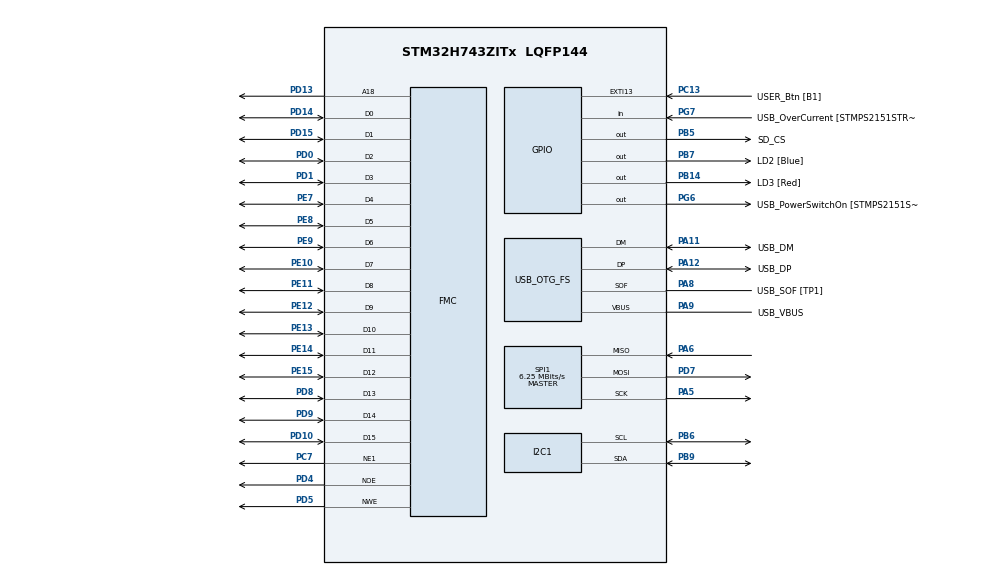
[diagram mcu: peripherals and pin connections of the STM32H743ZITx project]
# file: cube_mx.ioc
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I2C1.Timing=0x10C0ECFF
Mcu.Family=STM32H7
Mcu.Name=STM32H743ZITx
Mcu.Package=LQFP144
NVIC.I2C1_EV_IRQn=true\:10\:0\:true\:false\:true\:true\:true\:true
NVIC.PriorityGroup=NVIC_PRIORITYGROUP_4
NVIC.TIM2_IRQn=true\:1\:0\:true\:false\:true\:false\:true\:true
NVIC.TimeBase=TIM2_IRQn
NVIC.TimeBaseIP=TIM2
PA1.Signal=ETH_RX_CLK
PA10.GPIO_Label=USB_ID
PA10.Signal=USB_OTG_FS_ID
PA11.GPIO_Label=USB_DM
PA11.Mode=Device_Only
PA11.Signal=USB_OTG_FS_DM
PA12.GPIO_Label=USB_DP
PA12.Mode=Device_Only
PA12.Signal=USB_OTG_FS_DP
PA2.GPIO_Label=RMII_MDIO
PA2.Signal=ETH_MDIO
PA5.Mode=Full_Duplex_Master
PA5.Signal=SPI1_SCK
PA6.Mode=Full_Duplex_Master
PA6.Signal=SPI1_MISO
PA7.Signal=ETH_RX_DV
PA8.GPIO_Label=USB_SOF [TP1]
PA8.Mode=Activate_SOF_FS
PA8.Signal=USB_OTG_FS_SOF
PA9.GPIO_Label=USB_VBUS
PA9.Mode=Activate_VBUS
PA9.Signal=USB_OTG_FS_VBUS
PB13.GPIO_Label=RMII_TXD1
PB13.Signal=ETH_TXD1
PB14.GPIO_Label=LD3 [Red]
PB14.Signal=GPIO_Output
PB5.GPIO_Label=SD_CS
PB5.GPIO_Speed=GPIO_SPEED_FREQ_VERY_HIGH
PB5.PinState=GPIO_PIN_SET
PB5.Signal=GPIO_Output
PB6.Mode=I2C
PB6.Signal=I2C1_SCL
PB7.GPIO_Label=LD2 [Blue]
PB7.Signal=GPIO_Output
PB9.Mode=I2C
PB9.Signal=I2C1_SDA
PC1.GPIO_Label=RMII_MDC
PC1.Signal=ETH_MDC
PC13.GPIO_Label=USER_Btn [B1]
PC13.Signal=GPXTI13
PC14-OSC32_IN\ (OSC32_IN).Mode=LSE-External-Oscillator
PC14-OSC32_IN\ (OSC32_IN).Signal=RCC_OSC32_IN
PC15-OSC32_OUT\ (OSC32_OUT).Mode=LSE-External-Oscillator
PC15-OSC32_OUT\ (OSC32_OUT).Signal=RCC_OSC32_OUT
PC4.GPIO_Label=RMII_RXD0
PC4.Signal=ETH_RXD0
PC5.GPIO_Label=RMII_RXD1
PC5.Signal=ETH_RXD1
PC7.Mode=NorPsramChipSelect1_1
PC7.Signal=FMC_NE1
PD0.Signal=FMC_D2_DA2
PD1.Signal=FMC_D3_DA3
PD10.Signal=FMC_D15_DA15
PD13.Signal=FMC_A18
PD14.Signal=FMC_D0_DA0
PD15.Signal=FMC_D1_DA1
PD4.Signal=FMC_NOE
PD5.Signal=FMC_NWE
PD7.Mode=Full_Duplex_Master
PD7.Signal=SPI1_MOSI
PD8.Signal=FMC_D13_DA13
PD9.Signal=FMC_D14_DA14
PE10.Signal=FMC_D7_DA7
PE11.Signal=FMC_D8_DA8
PE12.Signal=FMC_D9_DA9
PE13.Signal=FMC_D10_DA10
PE14.Signal=FMC_D11_DA11
PE15.Signal=FMC_D12_DA12
PE7.Signal=FMC_D4_DA4
PE8.Signal=FMC_D5_DA5
PE9.Signal=FMC_D6_DA6
PG11.GPIO_Label=RMII_TX_EN
PG11.Signal=ETH_TX_EN
PG13.GPIO_Label=RMII_TXD0
PG13.Signal=ETH_TXD0
PG6.GPIO_Label=USB_PowerSwitchOn [STMPS2151STR_EN]
PG6.Signal=GPIO_Output
PG7.GPIO_Label=USB_OverCurrent [STMPS2151STR_FAULT]
PG7.Signal=GPIO_Input
PH0-OSC_IN\ (PH0).GPIO_Label=MCO
PH0-OSC_IN\ (PH0).Mode=HSE-External-Clock-Source
PH0-OSC_IN\ (PH0).Signal=RCC_OSC_IN
PH1-OSC_OUT\ (PH1).Signal=RCC_OSC_OUT
ProjectManager.HeapSize=0x200
ProjectManager.StackSize=0x400
ProjectManager.TargetToolchain=Makefile
RCC.48MHZClocksFreq_Value=24000000
RCC.ADCFreq_Value=16125000
RCC.AHBFreq_Value=216000000
RCC.APB1CLKDivider=RCC_HCLK_DIV4
RCC.APB1Freq_Value=100000000
RCC.APB1TimFreq_Value=108000000
RCC.APB2CLKDivider=RCC_HCLK_DIV2
RCC.APB2Freq_Value=100000000
RCC.APB2TimFreq_Value=216000000
RCC.APB3Freq_Value=100000000
RCC.APB4Freq_Value=100000000
RCC.CortexFreq_Value=400000000
RCC.D1PPRE=RCC_APB3_DIV2
RCC.D2PPRE1=RCC_APB1_DIV2
RCC.D2PPRE2=RCC_APB2_DIV2
RCC.D3PPRE=RCC_APB4_DIV2
RCC.DIVM1=1
RCC.DIVN1=100
RCC.DIVQ1=4
RCC.HCLKFreq_Value=200000000
RCC.HPRE=RCC_HCLK_DIV2
RCC.HSE_VALUE=8000000
RCC.HSI_VALUE=64000000
RCC.PLLM=25
RCC.PLLMUL=RCC_PLL_MUL9
RCC.PLLN=432
RCC.PLLQ=9
RCC.PLLSourceVirtual=RCC_PLLSOURCE_HSE
RCC.PRESCALERUSB=RCC_USBCLKSOURCE_PLL_DIV1_5
RCC.PWR_Regulator_Voltage_Scale=PWR_REGULATOR_VOLTAGE_SCALE1
RCC.SYSCLKFreq_VALUE=400000000
RCC.SYSCLKSource=RCC_SYSCLKSOURCE_PLLCLK
RCC.SYSCLKSourceVirtual=RCC_SYSCLKSOURCE_PLLCLK
RCC.USBCLockSelection=RCC_USBCLKSOURCE_HSI48
RCC.USBFreq_Value=48000000
RCC.VCOOutputFreq_Value=432000000
SH.FMC_A18.0=FMC_A18,A18_1
SH.FMC_D0_DA0.0=FMC_D0,16b-d1
SH.FMC_D10_DA10.0=FMC_D10,16b-d1
SH.FMC_D11_DA11.0=FMC_D11,16b-d1
SH.FMC_D12_DA12.0=FMC_D12,16b-d1
SH.FMC_D13_DA13.0=FMC_D13,16b-d1
SH.FMC_D14_DA14.0=FMC_D14,16b-d1
SH.FMC_D15_DA15.0=FMC_D15,16b-d1
SH.FMC_D1_DA1.0=FMC_D1,16b-d1
SH.FMC_D2_DA2.0=FMC_D2,16b-d1
SH.FMC_D3_DA3.0=FMC_D3,16b-d1
SH.FMC_D4_DA4.0=FMC_D4,16b-d1
SH.FMC_D5_DA5.0=FMC_D5,16b-d1
SH.FMC_D6_DA6.0=FMC_D6,16b-d1
SH.FMC_D7_DA7.0=FMC_D7,16b-d1
SH.FMC_D8_DA8.0=FMC_D8,16b-d1
SH.FMC_D9_DA9.0=FMC_D9,16b-d1
SH.FMC_NOE.0=FMC_NOE,Lcd1
SH.FMC_NWE.0=FMC_NWE,Lcd1
SPI1.BaudRatePrescaler=SPI_BAUDRATEPRESCALER_32
SPI1.CalculateBaudRate=6.25 MBits/s
SPI1.DataSize=SPI_DATASIZE_8BIT
SPI1.Direction=SPI_DIRECTION_2LINES
SPI1.Mode=SPI_MODE_MASTER
SPI1.VirtualType=VM_MASTER
USB_OTG_FS.VirtualMode=Device_Only
VP_SYS_VS_tim2.Mode=TIM2
board=NUCLEO-H743ZI

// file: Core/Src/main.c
/* USER CODE BEGIN Header */
/**
 ******************************************************************************
 * @file           : main.c
 * @brief          : Main program body
 ******************************************************************************
 * @attention
 *
 * Copyright (c) 2022 STMicroelectronics.
 * All rights reserved.
 *
 * This software is licensed under terms that can be found in the LICENSE file
 * in the root directory of this software component.
 * If no LICENSE file comes with this software, it is provided AS-IS.
 *
 ******************************************************************************
 */
/* USER CODE END Header */
#include "main.h"

/* USER CODE BEGIN Includes */
#include "application.h"

/* USER CODE END Includes */

I2C_HandleTypeDef hi2c1;

SPI_HandleTypeDef hspi1;

PCD_HandleTypeDef hpcd_USB_OTG_FS;

SRAM_HandleTypeDef hsram1;

void SystemClock_Config(void);
static void MX_GPIO_Init(void);
static void MX_USB_OTG_FS_PCD_Init(void);
static void MX_I2C1_Init(void);
static void MX_FMC_Init(void);
static void MX_SPI1_Init(void);

int main(void)
{

  /* MCU Configuration--------------------------------------------------------*/

  /* Reset of all peripherals, Initializes the Flash interface and the Systick. */
  HAL_Init();

  /* Configure the system clock */
  SystemClock_Config();

  /* Initialize all configured peripherals */
  MX_GPIO_Init();
  MX_USB_OTG_FS_PCD_Init();
  MX_I2C1_Init();
  MX_FMC_Init();
  MX_SPI1_Init();
  /* USER CODE BEGIN 2 */
  uint8_t appExitVal = application();
  if (appExitVal != 0)
  {
    // send error code via cli to user
  }
  /* USER CODE END 2 */

  /* Infinite loop */
  while (1)
  {

  }
}

void SystemClock_Config(void)
{
  RCC_OscInitTypeDef RCC_OscInitStruct = {0};
  RCC_ClkInitTypeDef RCC_ClkInitStruct = {0};

  /** Supply configuration update enable
  */
  HAL_PWREx_ConfigSupply(PWR_LDO_SUPPLY);

  /** Configure the main internal regulator output voltage
  */
  __HAL_PWR_VOLTAGESCALING_CONFIG(PWR_REGULATOR_VOLTAGE_SCALE1);

  while(!__HAL_PWR_GET_FLAG(PWR_FLAG_VOSRDY)) {}

  /** Initializes the RCC Oscillators according to the specified parameters
  * in the RCC_OscInitTypeDef structure.
  */
  RCC_OscInitStruct.OscillatorType = RCC_OSCILLATORTYPE_HSI48|RCC_OSCILLATORTYPE_HSE;
  RCC_OscInitStruct.HSEState = RCC_HSE_BYPASS;
  RCC_OscInitStruct.HSI48State = RCC_HSI48_ON;
  RCC_OscInitStruct.PLL.PLLState = RCC_PLL_ON;
  RCC_OscInitStruct.PLL.PLLSource = RCC_PLLSOURCE_HSE;
  RCC_OscInitStruct.PLL.PLLM = 1;
  RCC_OscInitStruct.PLL.PLLN = 100;
  RCC_OscInitStruct.PLL.PLLP = 2;
  RCC_OscInitStruct.PLL.PLLQ = 4;
  RCC_OscInitStruct.PLL.PLLR = 2;
  RCC_OscInitStruct.PLL.PLLRGE = RCC_PLL1VCIRANGE_3;
  RCC_OscInitStruct.PLL.PLLVCOSEL = RCC_PLL1VCOWIDE;
  RCC_OscInitStruct.PLL.PLLFRACN = 0;
  if (HAL_RCC_OscConfig(&RCC_OscInitStruct) != HAL_OK)
  {
    Error_Handler();
  }

  /** Initializes the CPU, AHB and APB buses clocks
  */
  RCC_ClkInitStruct.ClockType = RCC_CLOCKTYPE_HCLK|RCC_CLOCKTYPE_SYSCLK
                              |RCC_CLOCKTYPE_PCLK1|RCC_CLOCKTYPE_PCLK2
                              |RCC_CLOCKTYPE_D3PCLK1|RCC_CLOCKTYPE_D1PCLK1;
  RCC_ClkInitStruct.SYSCLKSource = RCC_SYSCLKSOURCE_PLLCLK;
  RCC_ClkInitStruct.SYSCLKDivider = RCC_SYSCLK_DIV1;
  RCC_ClkInitStruct.AHBCLKDivider = RCC_HCLK_DIV2;
  RCC_ClkInitStruct.APB3CLKDivider = RCC_APB3_DIV2;
  RCC_ClkInitStruct.APB1CLKDivider = RCC_APB1_DIV2;
  RCC_ClkInitStruct.APB2CLKDivider = RCC_APB2_DIV2;
  RCC_ClkInitStruct.APB4CLKDivider = RCC_APB4_DIV2;

  if (HAL_RCC_ClockConfig(&RCC_ClkInitStruct, FLASH_LATENCY_2) != HAL_OK)
  {
    Error_Handler();
  }
}

static void MX_I2C1_Init(void)
{

  hi2c1.Instance = I2C1;
  hi2c1.Init.Timing = 0x10C0ECFF;
  hi2c1.Init.OwnAddress1 = 0;
  hi2c1.Init.AddressingMode = I2C_ADDRESSINGMODE_7BIT;
  hi2c1.Init.DualAddressMode = I2C_DUALADDRESS_DISABLE;
  hi2c1.Init.OwnAddress2 = 0;
  hi2c1.Init.OwnAddress2Masks = I2C_OA2_NOMASK;
  hi2c1.Init.GeneralCallMode = I2C_GENERALCALL_DISABLE;
  hi2c1.Init.NoStretchMode = I2C_NOSTRETCH_DISABLE;
  if (HAL_I2C_Init(&hi2c1) != HAL_OK)
  {
    Error_Handler();
  }

  /** Configure Analogue filter
  */
  if (HAL_I2CEx_ConfigAnalogFilter(&hi2c1, I2C_ANALOGFILTER_ENABLE) != HAL_OK)
  {
    Error_Handler();
  }

  /** Configure Digital filter
  */
  if (HAL_I2CEx_ConfigDigitalFilter(&hi2c1, 0) != HAL_OK)
  {
    Error_Handler();
  }

}

static void MX_SPI1_Init(void)
{

  /* SPI1 parameter configuration*/
  hspi1.Instance = SPI1;
  hspi1.Init.Mode = SPI_MODE_MASTER;
  hspi1.Init.Direction = SPI_DIRECTION_2LINES;
  hspi1.Init.DataSize = SPI_DATASIZE_8BIT;
  hspi1.Init.CLKPolarity = SPI_POLARITY_LOW;
  hspi1.Init.CLKPhase = SPI_PHASE_1EDGE;
  hspi1.Init.NSS = SPI_NSS_SOFT;
  hspi1.Init.BaudRatePrescaler = SPI_BAUDRATEPRESCALER_32;
  hspi1.Init.FirstBit = SPI_FIRSTBIT_MSB;
  hspi1.Init.TIMode = SPI_TIMODE_DISABLE;
  hspi1.Init.CRCCalculation = SPI_CRCCALCULATION_DISABLE;
  hspi1.Init.CRCPolynomial = 0x0;
  hspi1.Init.NSSPMode = SPI_NSS_PULSE_ENABLE;
  hspi1.Init.NSSPolarity = SPI_NSS_POLARITY_LOW;
  hspi1.Init.FifoThreshold = SPI_FIFO_THRESHOLD_01DATA;
  hspi1.Init.TxCRCInitializationPattern = SPI_CRC_INITIALIZATION_ALL_ZERO_PATTERN;
  hspi1.Init.RxCRCInitializationPattern = SPI_CRC_INITIALIZATION_ALL_ZERO_PATTERN;
  hspi1.Init.MasterSSIdleness = SPI_MASTER_SS_IDLENESS_00CYCLE;
  hspi1.Init.MasterInterDataIdleness = SPI_MASTER_INTERDATA_IDLENESS_00CYCLE;
  hspi1.Init.MasterReceiverAutoSusp = SPI_MASTER_RX_AUTOSUSP_DISABLE;
  hspi1.Init.MasterKeepIOState = SPI_MASTER_KEEP_IO_STATE_DISABLE;
  hspi1.Init.IOSwap = SPI_IO_SWAP_DISABLE;
  if (HAL_SPI_Init(&hspi1) != HAL_OK)
  {
    Error_Handler();
  }

}

static void MX_USB_OTG_FS_PCD_Init(void)
{

  hpcd_USB_OTG_FS.Instance = USB_OTG_FS;
  hpcd_USB_OTG_FS.Init.dev_endpoints = 9;
  hpcd_USB_OTG_FS.Init.speed = PCD_SPEED_FULL;
  hpcd_USB_OTG_FS.Init.dma_enable = DISABLE;
  hpcd_USB_OTG_FS.Init.phy_itface = PCD_PHY_EMBEDDED;
  hpcd_USB_OTG_FS.Init.Sof_enable = ENABLE;
  hpcd_USB_OTG_FS.Init.low_power_enable = DISABLE;
  hpcd_USB_OTG_FS.Init.lpm_enable = DISABLE;
  hpcd_USB_OTG_FS.Init.battery_charging_enable = ENABLE;
  hpcd_USB_OTG_FS.Init.vbus_sensing_enable = ENABLE;
  hpcd_USB_OTG_FS.Init.use_dedicated_ep1 = DISABLE;
  if (HAL_PCD_Init(&hpcd_USB_OTG_FS) != HAL_OK)
  {
    Error_Handler();
  }

}

/* FMC initialization function */
static void MX_FMC_Init(void)
{

  FMC_NORSRAM_TimingTypeDef Timing = {0};

  /** Perform the SRAM1 memory initialization sequence
  */
  hsram1.Instance = FMC_NORSRAM_DEVICE;
  hsram1.Extended = FMC_NORSRAM_EXTENDED_DEVICE;
  /* hsram1.Init */
  hsram1.Init.NSBank = FMC_NORSRAM_BANK1;
  hsram1.Init.DataAddressMux = FMC_DATA_ADDRESS_MUX_DISABLE;
  hsram1.Init.MemoryType = FMC_MEMORY_TYPE_SRAM;
  hsram1.Init.MemoryDataWidth = FMC_NORSRAM_MEM_BUS_WIDTH_16;
  hsram1.Init.BurstAccessMode = FMC_BURST_ACCESS_MODE_DISABLE;
  hsram1.Init.WaitSignalPolarity = FMC_WAIT_SIGNAL_POLARITY_LOW;
  hsram1.Init.WaitSignalActive = FMC_WAIT_TIMING_BEFORE_WS;
  hsram1.Init.WriteOperation = FMC_WRITE_OPERATION_ENABLE;
  hsram1.Init.WaitSignal = FMC_WAIT_SIGNAL_DISABLE;
  hsram1.Init.ExtendedMode = FMC_EXTENDED_MODE_DISABLE;
  hsram1.Init.AsynchronousWait = FMC_ASYNCHRONOUS_WAIT_DISABLE;
  hsram1.Init.WriteBurst = FMC_WRITE_BURST_DISABLE;
  hsram1.Init.ContinuousClock = FMC_CONTINUOUS_CLOCK_SYNC_ONLY;
  hsram1.Init.WriteFifo = FMC_WRITE_FIFO_ENABLE;
  hsram1.Init.PageSize = FMC_PAGE_SIZE_NONE;
  /* Timing */
  Timing.AddressSetupTime = 15;
  Timing.AddressHoldTime = 15;
  Timing.DataSetupTime = 255;
  Timing.BusTurnAroundDuration = 15;
  Timing.CLKDivision = 16;
  Timing.DataLatency = 17;
  Timing.AccessMode = FMC_ACCESS_MODE_A;
  /* ExtTiming */

  if (HAL_SRAM_Init(&hsram1, &Timing, NULL) != HAL_OK)
  {
    Error_Handler( );
  }

}

static void MX_GPIO_Init(void)
{
  GPIO_InitTypeDef GPIO_InitStruct = {0};

  /* GPIO Ports Clock Enable */
  __HAL_RCC_GPIOC_CLK_ENABLE();
  __HAL_RCC_GPIOH_CLK_ENABLE();
  __HAL_RCC_GPIOA_CLK_ENABLE();
  __HAL_RCC_GPIOE_CLK_ENABLE();
  __HAL_RCC_GPIOB_CLK_ENABLE();
  __HAL_RCC_GPIOD_CLK_ENABLE();
  __HAL_RCC_GPIOG_CLK_ENABLE();

  /*Configure GPIO pin Output Level */
  HAL_GPIO_WritePin(GPIOB, LD3_Pin|LD2_Pin, GPIO_PIN_RESET);

  /*Configure GPIO pin Output Level */
  HAL_GPIO_WritePin(USB_PowerSwitchOn_GPIO_Port, USB_PowerSwitchOn_Pin, GPIO_PIN_RESET);

  /*Configure GPIO pin Output Level */
  HAL_GPIO_WritePin(SD_CS_GPIO_Port, SD_CS_Pin, GPIO_PIN_SET);

  /*Configure GPIO pin : USER_Btn_Pin */
  GPIO_InitStruct.Pin = USER_Btn_Pin;
  GPIO_InitStruct.Mode = GPIO_MODE_IT_RISING;
  GPIO_InitStruct.Pull = GPIO_NOPULL;
  HAL_GPIO_Init(USER_Btn_GPIO_Port, &GPIO_InitStruct);

  /*Configure GPIO pins : RMII_MDC_Pin RMII_RXD0_Pin RMII_RXD1_Pin */
  GPIO_InitStruct.Pin = RMII_MDC_Pin|RMII_RXD0_Pin|RMII_RXD1_Pin;
  GPIO_InitStruct.Mode = GPIO_MODE_AF_PP;
  GPIO_InitStruct.Pull = GPIO_NOPULL;
  GPIO_InitStruct.Speed = GPIO_SPEED_FREQ_LOW;
  GPIO_InitStruct.Alternate = GPIO_AF11_ETH;
  HAL_GPIO_Init(GPIOC, &GPIO_InitStruct);

  /*Configure GPIO pins : PA1 RMII_MDIO_Pin PA7 */
  GPIO_InitStruct.Pin = GPIO_PIN_1|RMII_MDIO_Pin|GPIO_PIN_7;
  GPIO_InitStruct.Mode = GPIO_MODE_AF_PP;
  GPIO_InitStruct.Pull = GPIO_NOPULL;
  GPIO_InitStruct.Speed = GPIO_SPEED_FREQ_LOW;
  GPIO_InitStruct.Alternate = GPIO_AF11_ETH;
  HAL_GPIO_Init(GPIOA, &GPIO_InitStruct);

  /*Configure GPIO pin : RMII_TXD1_Pin */
  GPIO_InitStruct.Pin = RMII_TXD1_Pin;
  GPIO_InitStruct.Mode = GPIO_MODE_AF_PP;
  GPIO_InitStruct.Pull = GPIO_NOPULL;
  GPIO_InitStruct.Speed = GPIO_SPEED_FREQ_LOW;
  GPIO_InitStruct.Alternate = GPIO_AF11_ETH;
  HAL_GPIO_Init(RMII_TXD1_GPIO_Port, &GPIO_InitStruct);

  /*Configure GPIO pins : LD3_Pin LD2_Pin */
  GPIO_InitStruct.Pin = LD3_Pin|LD2_Pin;
  GPIO_InitStruct.Mode = GPIO_MODE_OUTPUT_PP;
  GPIO_InitStruct.Pull = GPIO_NOPULL;
  GPIO_InitStruct.Speed = GPIO_SPEED_FREQ_LOW;
  HAL_GPIO_Init(GPIOB, &GPIO_InitStruct);

  /*Configure GPIO pin : USB_PowerSwitchOn_Pin */
  GPIO_InitStruct.Pin = USB_PowerSwitchOn_Pin;
  GPIO_InitStruct.Mode = GPIO_MODE_OUTPUT_PP;
  GPIO_InitStruct.Pull = GPIO_NOPULL;
  GPIO_InitStruct.Speed = GPIO_SPEED_FREQ_LOW;
  HAL_GPIO_Init(USB_PowerSwitchOn_GPIO_Port, &GPIO_InitStruct);

  /*Configure GPIO pin : USB_OverCurrent_Pin */
  GPIO_InitStruct.Pin = USB_OverCurrent_Pin;
  GPIO_InitStruct.Mode = GPIO_MODE_INPUT;
  GPIO_InitStruct.Pull = GPIO_NOPULL;
  HAL_GPIO_Init(USB_OverCurrent_GPIO_Port, &GPIO_InitStruct);

  /*Configure GPIO pins : RMII_TX_EN_Pin RMII_TXD0_Pin */
  GPIO_InitStruct.Pin = RMII_TX_EN_Pin|RMII_TXD0_Pin;
  GPIO_InitStruct.Mode = GPIO_MODE_AF_PP;
  GPIO_InitStruct.Pull = GPIO_NOPULL;
  GPIO_InitStruct.Speed = GPIO_SPEED_FREQ_LOW;
  GPIO_InitStruct.Alternate = GPIO_AF11_ETH;
  HAL_GPIO_Init(GPIOG, &GPIO_InitStruct);

  /*Configure GPIO pin : SD_CS_Pin */
  GPIO_InitStruct.Pin = SD_CS_Pin;
  GPIO_InitStruct.Mode = GPIO_MODE_OUTPUT_PP;
  GPIO_InitStruct.Pull = GPIO_NOPULL;
  GPIO_InitStruct.Speed = GPIO_SPEED_FREQ_VERY_HIGH;
  HAL_GPIO_Init(SD_CS_GPIO_Port, &GPIO_InitStruct);

}

void HAL_TIM_PeriodElapsedCallback(TIM_HandleTypeDef *htim)
{
  if (htim->Instance == TIM2) {
    HAL_IncTick();
  }
}

void Error_Handler(void)
{
  __disable_irq();
  while (1)
  {
  }
}
